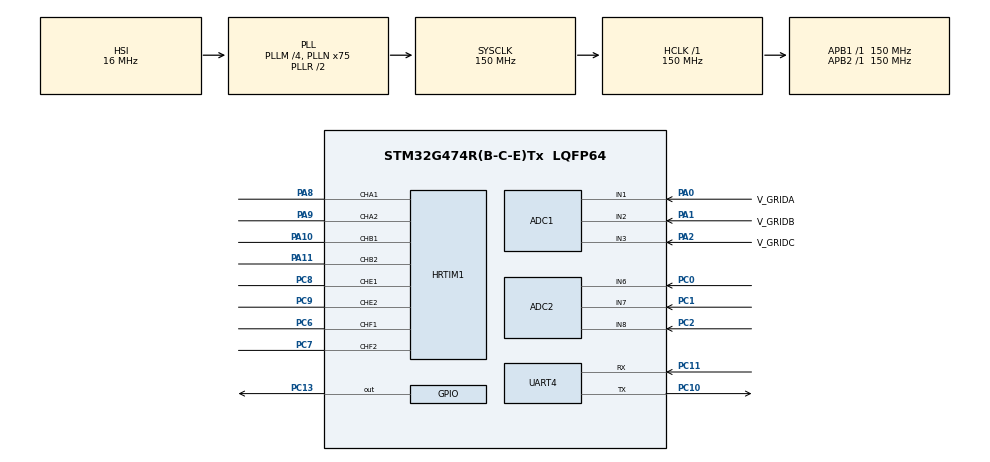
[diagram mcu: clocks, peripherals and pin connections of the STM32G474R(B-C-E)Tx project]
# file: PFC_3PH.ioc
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ADC1.Channel-0\#ChannelRegularConversion=ADC_CHANNEL_1
ADC1.Channel-1\#ChannelRegularConversion=ADC_CHANNEL_2
ADC1.Channel-2\#ChannelRegularConversion=ADC_CHANNEL_3
ADC1.DMAContinuousRequests=ENABLE
ADC1.EOCSelection=ADC_EOC_SINGLE_CONV
ADC1.ExternalTrigConv=ADC_EXTERNALTRIG_HRTIM_TRG1
ADC1.ExternalTrigConvEdge=ADC_EXTERNALTRIGCONVEDGE_RISINGFALLING
ADC1.NbrOfConversion=3
ADC1.NbrOfConversionFlag=1
ADC1.OffsetNumber-0\#ChannelRegularConversion=ADC_OFFSET_NONE
ADC1.OffsetNumber-1\#ChannelRegularConversion=ADC_OFFSET_NONE
ADC1.OffsetNumber-2\#ChannelRegularConversion=ADC_OFFSET_NONE
ADC1.Rank-0\#ChannelRegularConversion=1
ADC1.Rank-1\#ChannelRegularConversion=2
ADC1.Rank-2\#ChannelRegularConversion=3
ADC1.SamplingTime-0\#ChannelRegularConversion=ADC_SAMPLETIME_6CYCLES_5
ADC1.SamplingTime-1\#ChannelRegularConversion=ADC_SAMPLETIME_6CYCLES_5
ADC1.SamplingTime-2\#ChannelRegularConversion=ADC_SAMPLETIME_6CYCLES_5
ADC1.master=1
ADC2.Channel-0\#ChannelRegularConversion=ADC_CHANNEL_6
ADC2.NbrOfConversionFlag=1
ADC2.OffsetNumber-0\#ChannelRegularConversion=ADC_OFFSET_NONE
ADC2.Rank-0\#ChannelRegularConversion=1
ADC2.SamplingTime-0\#ChannelRegularConversion=ADC_SAMPLETIME_2CYCLES_5
Dma.ADC1.0.Direction=DMA_PERIPH_TO_MEMORY
Dma.ADC1.0.EventEnable=DISABLE
Dma.ADC1.0.Instance=DMA1_Channel1
Dma.ADC1.0.MemDataAlignment=DMA_MDATAALIGN_HALFWORD
Dma.ADC1.0.MemInc=DMA_MINC_ENABLE
Dma.ADC1.0.Mode=DMA_CIRCULAR
Dma.ADC1.0.PeriphDataAlignment=DMA_PDATAALIGN_HALFWORD
Dma.ADC1.0.PeriphInc=DMA_PINC_DISABLE
Dma.ADC1.0.Polarity=HAL_DMAMUX_REQ_GEN_RISING
Dma.ADC1.0.Priority=DMA_PRIORITY_LOW
Dma.ADC1.0.RequestNumber=1
Dma.ADC1.0.SignalID=NONE
Dma.ADC1.0.SyncEnable=DISABLE
Dma.ADC1.0.SyncPolarity=HAL_DMAMUX_SYNC_NO_EVENT
Dma.ADC1.0.SyncRequestNumber=1
Dma.ADC1.0.SyncSignalID=NONE
Dma.Request0=ADC1
Dma.Request1=UART4_TX
Dma.UART4_TX.1.Direction=DMA_MEMORY_TO_PERIPH
Dma.UART4_TX.1.EventEnable=DISABLE
Dma.UART4_TX.1.Instance=DMA1_Channel2
Dma.UART4_TX.1.MemDataAlignment=DMA_MDATAALIGN_BYTE
Dma.UART4_TX.1.MemInc=DMA_MINC_ENABLE
Dma.UART4_TX.1.Mode=DMA_NORMAL
Dma.UART4_TX.1.PeriphDataAlignment=DMA_PDATAALIGN_BYTE
Dma.UART4_TX.1.PeriphInc=DMA_PINC_DISABLE
Dma.UART4_TX.1.Polarity=HAL_DMAMUX_REQ_GEN_RISING
Dma.UART4_TX.1.Priority=DMA_PRIORITY_LOW
Dma.UART4_TX.1.RequestNumber=1
Dma.UART4_TX.1.SignalID=NONE
Dma.UART4_TX.1.SyncEnable=DISABLE
Dma.UART4_TX.1.SyncPolarity=HAL_DMAMUX_SYNC_NO_EVENT
Dma.UART4_TX.1.SyncRequestNumber=1
Dma.UART4_TX.1.SyncSignalID=NONE
HRTIM1.ADCTrigger1_Source1=HRTIM_ADCTRIGGEREVENT13_TIMERA_PERIOD
HRTIM1.ADCTrigger_Id1=HRTIM_ADCTRIGGER_1
HRTIM1.ADCTrigger_Id2=__NULL
HRTIM1.ADCTrigger_Id3=__NULL
HRTIM1.CaptureUnit1-Output_TA1TA2=__NULL
HRTIM1.CompareUnit1-Output_TA1TA2=HRTIM_COMPAREUNIT_1
HRTIM1.CompareUnit2-Output_TA1TA2=__NULL
HRTIM1.CompareUnit3-Output_TA1TA2=HRTIM_COMPAREUNIT_3
HRTIM1.CompareValue1-Output_TA1TA2=30000
HRTIM1.CompareValue3-Output_TA1TA2=30000
HRTIM1.InterruptRequests1-Output_TA1TA2=HRTIM_TIM_IT_UPD
HRTIM1.NumberADCTriggerSource1=1
HRTIM1.NumberInterruptRequests-Output_TA1TA2=1
HRTIM1.NumberResetSource1-Output_TA1TA2=1
HRTIM1.NumberSetSource1-Output_TA1TA2=1
HRTIM1.Periode_TA=60000
HRTIM1.PreloadEnable-Output_TA1TA2=HRTIM_PRELOAD_ENABLED
HRTIM1.PrescalerRatio_TA=HRTIM_PRESCALERRATIO_MUL4
HRTIM1.RepetitionUpdate-Output_TA1TA2=HRTIM_UPDATEONREPETITION_ENABLED
HRTIM1.ResetOutput1_Source1-Output_TA1TA2=HRTIM_OUTPUTRESET_TIMCMP1
HRTIM1.SetOutput1_Source1-Output_TA1TA2=HRTIM_OUTPUTSET_TIMCMP1
HRTIM1.UpDownMode-Output_TA1TA2=HRTIM_TIMERUPDOWNMODE_UP
Mcu.Family=STM32G4
Mcu.Name=STM32G474R(B-C-E)Tx
Mcu.Package=LQFP64
NVIC.ADC1_2_IRQn=true\:0\:0\:false\:false\:true\:true\:true\:true
NVIC.DMA1_Channel1_IRQn=true\:0\:0\:false\:false\:true\:false\:true\:true
NVIC.DMA1_Channel2_IRQn=true\:0\:0\:false\:false\:true\:true\:true\:true
NVIC.HRTIM1_TIMA_IRQn=true\:0\:0\:false\:false\:true\:true\:true\:true
NVIC.PriorityGroup=NVIC_PRIORITYGROUP_4
PA0.GPIO_Label=V_GRIDA
PA0.Mode=IN1-Single-Ended
PA0.Signal=ADC1_IN1
PA1.GPIO_Label=V_GRIDB
PA1.Mode=IN2-Single-Ended
PA1.Signal=ADC1_IN2
PA10.Mode=Output_TB1TB2
PA10.Signal=HRTIM1_CHB1
PA11.Mode=Output_TB1TB2
PA11.Signal=HRTIM1_CHB2
PA13.Mode=Serial_Wire
PA13.Signal=SYS_JTMS-SWDIO
PA14.Mode=Serial_Wire
PA14.Signal=SYS_JTCK-SWCLK
PA2.GPIO_Label=V_GRIDC
PA2.Mode=IN3-Single-Ended
PA2.Signal=ADC1_IN3
PA8.Mode=Output_TA1TA2
PA8.Signal=HRTIM1_CHA1
PA9.Mode=Output_TA1TA2
PA9.Signal=HRTIM1_CHA2
PC0.Mode=IN6-Single-Ended
PC0.Signal=ADC2_IN6
PC1.Mode=IN7-Single-Ended
PC1.Signal=ADC2_IN7
PC10.Mode=Asynchronous
PC10.Signal=UART4_TX
PC11.Mode=Asynchronous
PC11.Signal=UART4_RX
PC13.Signal=GPIO_Output
PC2.Mode=IN8-Single-Ended
PC2.Signal=ADC2_IN8
PC6.Mode=Output_TF1TF2
PC6.Signal=HRTIM1_CHF1
PC7.Mode=Output_TF1TF2
PC7.Signal=HRTIM1_CHF2
PC8.Mode=Output_TE1TE2
PC8.Signal=HRTIM1_CHE1
PC9.Mode=Output_TE1TE2
PC9.Signal=HRTIM1_CHE2
PF0-OSC_IN.Mode=HSE-External-Oscillator
PF0-OSC_IN.Signal=RCC_OSC_IN
PF1-OSC_OUT.Mode=HSE-External-Oscillator
PF1-OSC_OUT.Signal=RCC_OSC_OUT
ProjectManager.HeapSize=0x200
ProjectManager.StackSize=0x400
ProjectManager.TargetToolchain=Makefile
RCC.ADC12Freq_Value=150000000
RCC.ADC345Freq_Value=150000000
RCC.AHBFreq_Value=150000000
RCC.APB1Freq_Value=150000000
RCC.APB1TimFreq_Value=150000000
RCC.APB2Freq_Value=150000000
RCC.APB2TimFreq_Value=150000000
RCC.CortexFreq_Value=150000000
RCC.EXTERNAL_CLOCK_VALUE=12288000
RCC.HCLKFreq_Value=150000000
RCC.HSE_VALUE=8000000
RCC.HSI48_VALUE=48000000
RCC.HSI_VALUE=16000000
RCC.LSE_VALUE=32768
RCC.PLLM=RCC_PLLM_DIV4
RCC.PLLN=75
RCC.SYSCLKFreq_VALUE=150000000
RCC.SYSCLKSource=RCC_SYSCLKSOURCE_PLLCLK
RCC.USBFreq_Value=150000000
RCC.VCOOutputFreq_Value=300000000
STMicroelectronics.X-CUBE-ALGOBUILD.1.3.0.LibraryCcDSPOoLibraryJjDSPOoLibrary=true
TIM1.Prescaler=150-1
VP_STMicroelectronics.X-CUBE-ALGOBUILD_VS_DSPOoLibraryJjLibrary_1.3.0_1.3.0.Mode=DSPOoLibraryJjLibrary
VP_SYS_VS_DBSignals.Mode=DisableDeadBatterySignals
VP_TIM1_VS_ClockSourceINT.Mode=Internal
board=custom

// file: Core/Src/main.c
/* USER CODE BEGIN Header */
/**
  ******************************************************************************
  * @file           : main.c
  * @brief          : Main program body
  ******************************************************************************
  * @attention
  *
  * Copyright (c) 2023 STMicroelectronics.
  * All rights reserved.
  *
  * This software is licensed under terms that can be found in the LICENSE file
  * in the root directory of this software component.
  * If no LICENSE file comes with this software, it is provided AS-IS.
  *
  ******************************************************************************
  */
/* USER CODE END Header */
#include "main.h"
#include "adc.h"
#include "dma.h"
#include "hrtim.h"
#include "tim.h"
#include "usart.h"
#include "gpio.h"

/* USER CODE BEGIN Includes */
#include "inc.h"
/* USER CODE END Includes */

void SystemClock_Config(void);

int main(void)
{

  /* MCU Configuration--------------------------------------------------------*/

  /* Reset of all peripherals, Initializes the Flash interface and the Systick. */
  HAL_Init();

  /* Configure the system clock */
  SystemClock_Config();

  /* Initialize all configured peripherals */
  MX_GPIO_Init();
  MX_DMA_Init();
  MX_ADC1_Init();
  MX_ADC2_Init();
  MX_HRTIM1_Init();
  MX_UART4_Init();
  MX_TIM1_Init();
  /* USER CODE BEGIN 2 */
  Task_Init();
  /* USER CODE END 2 */

  /* Infinite loop */
  while (1)
  {

    /* USER CODE BEGIN 3 */
    Task_Do();
  }
  /* USER CODE END 3 */
}

void SystemClock_Config(void)
{
  RCC_OscInitTypeDef RCC_OscInitStruct = {0};
  RCC_ClkInitTypeDef RCC_ClkInitStruct = {0};

  /** Configure the main internal regulator output voltage
  */
  HAL_PWREx_ControlVoltageScaling(PWR_REGULATOR_VOLTAGE_SCALE1);

  /** Initializes the RCC Oscillators according to the specified parameters
  * in the RCC_OscInitTypeDef structure.
  */
  RCC_OscInitStruct.OscillatorType = RCC_OSCILLATORTYPE_HSI;
  RCC_OscInitStruct.HSIState = RCC_HSI_ON;
  RCC_OscInitStruct.HSICalibrationValue = RCC_HSICALIBRATION_DEFAULT;
  RCC_OscInitStruct.PLL.PLLState = RCC_PLL_ON;
  RCC_OscInitStruct.PLL.PLLSource = RCC_PLLSOURCE_HSI;
  RCC_OscInitStruct.PLL.PLLM = RCC_PLLM_DIV4;
  RCC_OscInitStruct.PLL.PLLN = 75;
  RCC_OscInitStruct.PLL.PLLP = RCC_PLLP_DIV2;
  RCC_OscInitStruct.PLL.PLLQ = RCC_PLLQ_DIV2;
  RCC_OscInitStruct.PLL.PLLR = RCC_PLLR_DIV2;
  if (HAL_RCC_OscConfig(&RCC_OscInitStruct) != HAL_OK)
  {
    Error_Handler();
  }

  /** Initializes the CPU, AHB and APB buses clocks
  */
  RCC_ClkInitStruct.ClockType = RCC_CLOCKTYPE_HCLK|RCC_CLOCKTYPE_SYSCLK
                              |RCC_CLOCKTYPE_PCLK1|RCC_CLOCKTYPE_PCLK2;
  RCC_ClkInitStruct.SYSCLKSource = RCC_SYSCLKSOURCE_PLLCLK;
  RCC_ClkInitStruct.AHBCLKDivider = RCC_SYSCLK_DIV1;
  RCC_ClkInitStruct.APB1CLKDivider = RCC_HCLK_DIV1;
  RCC_ClkInitStruct.APB2CLKDivider = RCC_HCLK_DIV1;

  if (HAL_RCC_ClockConfig(&RCC_ClkInitStruct, FLASH_LATENCY_4) != HAL_OK)
  {
    Error_Handler();
  }
}

void Error_Handler(void)
{
  __disable_irq();
  while (1)
  {
  }
}
